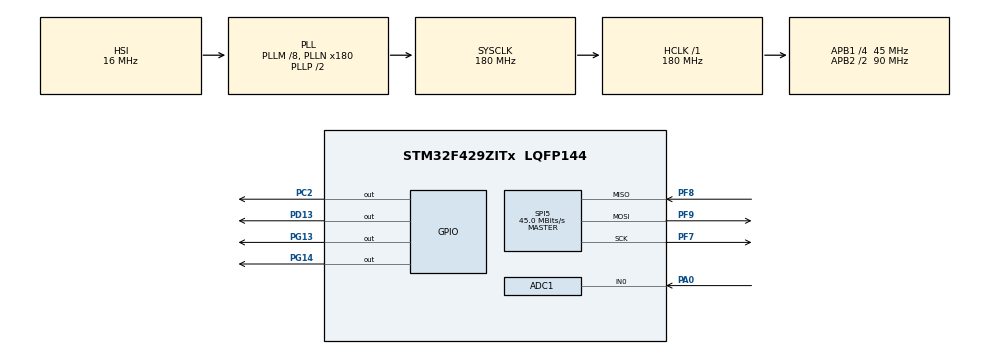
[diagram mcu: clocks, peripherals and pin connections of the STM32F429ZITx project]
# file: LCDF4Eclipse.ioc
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ADC1.Channel-0\#ChannelRegularConversion=ADC_CHANNEL_0
ADC1.NbrOfConversionFlag=1
ADC1.Rank-0\#ChannelRegularConversion=1
ADC1.Resolution=ADC_RESOLUTION_12B
ADC1.SamplingTime-0\#ChannelRegularConversion=ADC_SAMPLETIME_3CYCLES
ADC1.master=1
Mcu.Family=STM32F4
Mcu.Name=STM32F429ZITx
Mcu.Package=LQFP144
NVIC.PriorityGroup=NVIC_PRIORITYGROUP_0
PA0/WKUP.Signal=ADCx_IN0
PC2.Signal=GPIO_Output
PD13.Signal=GPIO_Output
PF7.Mode=Full_Duplex_Master
PF7.Signal=SPI5_SCK
PF8.Mode=Full_Duplex_Master
PF8.Signal=SPI5_MISO
PF9.Mode=Full_Duplex_Master
PF9.Signal=SPI5_MOSI
PG13.Signal=GPIO_Output
PG14.Signal=GPIO_Output
PH0/OSC_IN.Mode=HSE-External-Oscillator
PH0/OSC_IN.Signal=RCC_OSC_IN
PH1/OSC_OUT.Mode=HSE-External-Oscillator
PH1/OSC_OUT.Signal=RCC_OSC_OUT
ProjectManager.HeapSize=0x200
ProjectManager.StackSize=0x400
ProjectManager.TargetToolchain=SW4STM32
RCC.48MHZClocksFreq_Value=51428571.428571425
RCC.AHBFreq_Value=180000000
RCC.APB1CLKDivider=RCC_HCLK_DIV4
RCC.APB1Freq_Value=45000000
RCC.APB1TimFreq_Value=90000000
RCC.APB2CLKDivider=RCC_HCLK_DIV2
RCC.APB2Freq_Value=90000000
RCC.APB2TimFreq_Value=180000000
RCC.CortexFreq_Value=180000000
RCC.HCLKFreq_Value=180000000
RCC.HSE_VALUE=8000000
RCC.HSI_VALUE=16000000
RCC.LSE_VALUE=32768
RCC.PLLM=8
RCC.PLLN=180
RCC.PLLQ=7
RCC.SYSCLKFreq_VALUE=180000000
RCC.SYSCLKSource=RCC_SYSCLKSOURCE_PLLCLK
RCC.VCOOutputFreq_Value=360000000
SH.ADCx_IN0.0=ADC1_IN0,IN0
SPI5.CalculateBaudRate=45.0 MBits/s
SPI5.Direction=SPI_DIRECTION_2LINES
SPI5.Mode=SPI_MODE_MASTER
SPI5.VirtualType=VM_MASTER
board=32F429IDISCOVERY

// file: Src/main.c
/* USER CODE BEGIN Header */
/**
  ******************************************************************************
  * @file           : main.c
  * @brief          : Main program body
  ******************************************************************************
  * @attention
  *
  * <h2><center>&copy; Copyright (c) 2020 STMicroelectronics.
  * All rights reserved.</center></h2>
  *
  * This software component is licensed by ST under BSD 3-Clause license,
  * the "License"; You may not use this file except in compliance with the
  * License. You may obtain a copy of the License at:
  *                        opensource.org/licenses/BSD-3-Clause
  *
  ******************************************************************************
  */
/* USER CODE END Header */

#include "main.h"
#include "adc.h"
#include "spi.h"
#include "gpio.h"
#include "LCDLib.h"
#include "LCDGFX.h"
#include "STM32.h"
#include "CNC.h"

void SystemClock_Config(void);

int main(void)
{

  /* MCU Configuration--------------------------------------------------------*/

  /* Reset of all peripherals, Initializes the Flash interface and the Systick. */
  HAL_Init();

  /* Configure the system clock */
  SystemClock_Config();

  /* Initialize all configured peripherals */
  MX_GPIO_Init();
  MX_SPI5_Init();
  MX_ADC1_Init();
  /* USER CODE BEGIN 2 */
  ILI9341_Init();
  ILI9341_Set_Rotation(SCREEN_VERTICAL_1);
  ILI9341_Fill_Screen(WHITE);
  /* USER CODE END 2 */

  /* Infinite loop */
    /* USER CODE BEGIN WHILE */
    uint32_t adcValue = 0;
    uint32_t adcReadValue = 0;
    uint32_t pastadcValue = 0;

    while (1)
    {
  	  HAL_ADC_Start(&hadc1);
  	  	  if(HAL_ADC_PollForConversion(&hadc1, 5)==HAL_OK)
  	  	  {
  	  		  pastadcValue = adcReadValue;
  	  		  adcReadValue = HAL_ADC_GetValue(&hadc1);
  	  		  adcValue = (adcReadValue >> 2) - 320;
  	  		  /*
  	  		   * shift by two to bring range of values down to 0 to 1024
  	  		   * subtract by 320 t0 get range to -320 to 704
  	  		   */
  	  		  if ((adcReadValue - pastadcValue) <= -2 && (adcReadValue - pastadcValue) >= 2){
  	  		  	  	  ILI9341_Fill_Screen(WHITE);
  	  		  	  	  ILI9341_printImage(13, adcValue-650, 214, 161, CNC, sizeof(CNC));
  	  		  	  	  ILI9341_printImage(13, adcValue-300, 214, 161, CNC, sizeof(CNC));
  	  		  	  	  ILI9341_Draw_Text("Sujith Naapa Ramesh", 0, adcValue-90, BLACK, 2, WHITE);
  	  		  	  	  ILI9341_Draw_Text("2 Highland Ln", 0, adcValue-60, BLACK, 2, WHITE);
  	  		  	  	  ILI9341_Draw_Text("Littleton, MA 01460", 0, adcValue-30, BLACK, 2, WHITE);
  	  		  		  ILI9341_Draw_Text("Sujith Naapa Ramesh", 0, adcValue, BLACK, 2, WHITE);
  	  		  		  ILI9341_Draw_Text("2 Highland Ln", 0, adcValue+30, BLACK, 2, WHITE);
  	  		  		  ILI9341_Draw_Text("Littleton, MA 01460", 0, adcValue+60, BLACK, 2, WHITE);
  	  		  		  ILI9341_printImage(0, adcValue+90, 80, 130, STM32, sizeof(STM32));
  	  		  		  ILI9341_printImage(13, adcValue+240, 214, 161, CNC, sizeof(CNC));
  	  		  		  ILI9341_printImage(13, adcValue+450, 214, 161, CNC, sizeof(CNC));
  	  		  		  //HAL_GPIO_TogglePin(GPIOG, GPIO_PIN_13|GPIO_PIN_14);
  	  		  		  //HAL_Delay(1000);
  	  		  }
  	  	  }
    }
    /* USER CODE END 3 */}

void SystemClock_Config(void)
{
  RCC_OscInitTypeDef RCC_OscInitStruct = {0};
  RCC_ClkInitTypeDef RCC_ClkInitStruct = {0};

  /** Configure the main internal regulator output voltage
  */
  __HAL_RCC_PWR_CLK_ENABLE();
  __HAL_PWR_VOLTAGESCALING_CONFIG(PWR_REGULATOR_VOLTAGE_SCALE1);
  /** Initializes the CPU, AHB and APB busses clocks
  */
  RCC_OscInitStruct.OscillatorType = RCC_OSCILLATORTYPE_HSI;
  RCC_OscInitStruct.HSIState = RCC_HSI_ON;
  RCC_OscInitStruct.HSICalibrationValue = RCC_HSICALIBRATION_DEFAULT;
  RCC_OscInitStruct.PLL.PLLState = RCC_PLL_ON;
  RCC_OscInitStruct.PLL.PLLSource = RCC_PLLSOURCE_HSI;
  RCC_OscInitStruct.PLL.PLLM = 8;
  RCC_OscInitStruct.PLL.PLLN = 180;
  RCC_OscInitStruct.PLL.PLLP = RCC_PLLP_DIV2;
  RCC_OscInitStruct.PLL.PLLQ = 7;
  if (HAL_RCC_OscConfig(&RCC_OscInitStruct) != HAL_OK)
  {
    Error_Handler();
  }
  /** Activate the Over-Drive mode
  */
  if (HAL_PWREx_EnableOverDrive() != HAL_OK)
  {
    Error_Handler();
  }
  /** Initializes the CPU, AHB and APB busses clocks
  */
  RCC_ClkInitStruct.ClockType = RCC_CLOCKTYPE_HCLK|RCC_CLOCKTYPE_SYSCLK
                              |RCC_CLOCKTYPE_PCLK1|RCC_CLOCKTYPE_PCLK2;
  RCC_ClkInitStruct.SYSCLKSource = RCC_SYSCLKSOURCE_PLLCLK;
  RCC_ClkInitStruct.AHBCLKDivider = RCC_SYSCLK_DIV1;
  RCC_ClkInitStruct.APB1CLKDivider = RCC_HCLK_DIV4;
  RCC_ClkInitStruct.APB2CLKDivider = RCC_HCLK_DIV2;

  if (HAL_RCC_ClockConfig(&RCC_ClkInitStruct, FLASH_LATENCY_5) != HAL_OK)
  {
    Error_Handler();
  }
}

void Error_Handler(void)
{
}

/************************ (C) COPYRIGHT STMicroelectronics *****END OF FILE****/
